# STM32G081 register map
File version: 1.8
CPU: CM0 r0p1, little endian, MPU, no FPU, 2 interrupt priority bits
Registers are 32-bit, read-write, reset 0x0 unless marked. A register's access mark holds for its fields unless they carry their own. Offsets are from the block's base; [hi:lo] are bit positions; 'fields as' and 'values as' point back to an identical list.

## UCPD1 — USB Power Delivery interface
Base 0x4000A000
Same registers: UCPD2 0x4000A400
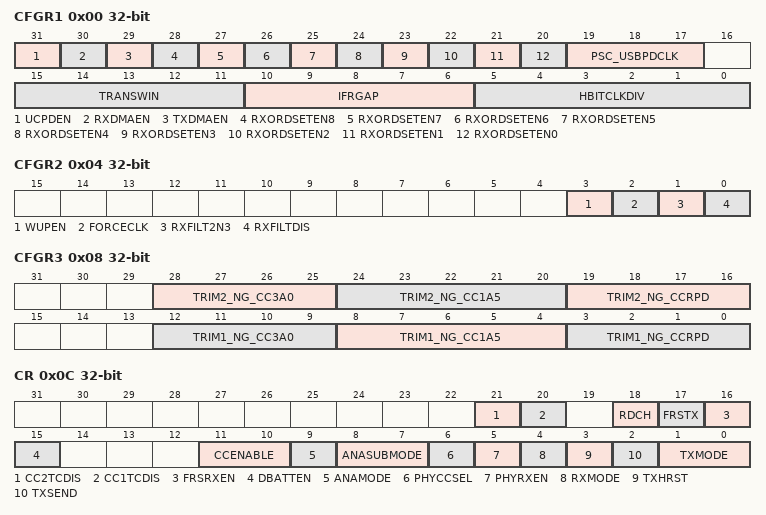
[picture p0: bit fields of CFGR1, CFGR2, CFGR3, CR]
0x00 CFGR1 — UCPD configuration register
  [31] UCPDEN
    0=Disabled (UCPD peripheral disabled); 1=Enabled (UCPD peripheral enabled)
  [30] RXDMAEN
    0=Disabled (DMA mode for reception disabled); 1=Enabled (DMA mode for reception enabled)
  [29] TXDMAEN
    0=Disabled (DMA mode for transmission disabled); 1=Enabled (DMA mode for transmission enabled)
  [28] RXORDSETEN8 — SOP extension #2
    0=Disabled (Flag disabled); 1=Enabled (Flag enabled)
  [27] RXORDSETEN7 — SOP extension #1
    0=Disabled (Flag disabled); 1=Enabled (Flag enabled)
  [26] RXORDSETEN6 — SOP'' Debug
    0=Disabled (Flag disabled); 1=Enabled (Flag enabled)
  [25] RXORDSETEN5 — SOP'_Debug
    0=Disabled (Flag disabled); 1=Enabled (Flag enabled)
  [24] RXORDSETEN4 — Cable Detect reset
    0=Disabled (Flag disabled); 1=Enabled (Flag enabled)
  [23] RXORDSETEN3 — Hard Reset detection
    0=Disabled (Flag disabled); 1=Enabled (Flag enabled)
  [22] RXORDSETEN2 — SOP'' detection
    0=Disabled (Flag disabled); 1=Enabled (Flag enabled)
  [21] RXORDSETEN1 — SOP' detection
    0=Disabled (Flag disabled); 1=Enabled (Flag enabled)
  [20] RXORDSETEN0 — SOP detection
    0=Disabled (Flag disabled); 1=Enabled (Flag enabled)
  [19:17] PSC_USBPDCLK
    0=Div1 (Divide by 1); 1=Div2 (Divide by 2); 2=Div4 (Divide by 4); 3=Div8 (Divide by 8); 4=Div16 (Divide by 16)
  [15:11] TRANSWIN range 1..31
  [10:6] IFRGAP range 1..31
  [5:0] HBITCLKDIV
0x04 CFGR2 — UCPD configuration register 2
  [3] WUPEN
    0=Disabled; 1=Enabled
  [2] FORCECLK
    0=NoForce (Do not force clock request); 1=Force clock request
  [1] RXFILT2N3
    0=Samp3 (3 samples); 1=Samp2 (2 samples)
  [0] RXFILTDIS
    0=Enabled (Rx pre-filter enabled); 1=Disabled (Rx pre-filter disabled)
0x08 CFGR3 — UCPD configuration register 3
  [28:25] TRIM2_NG_CC3A0, [24:20] TRIM2_NG_CC1A5 range 0..15, [19:16] TRIM2_NG_CCRPD, [12:9] TRIM1_NG_CC3A0, [8:4] TRIM1_NG_CC1A5 range 0..15, [3:0] TRIM1_NG_CCRPD
0x0C CR — UCPD control register
  [21] CC2TCDIS
    0=Enabled (Type-C detector on the CCx line enabled); 1=Disabled (Type-C detector on the CCx line disabled)
  [20] CC1TCDIS
    values as CC2TCDIS
  [18] RDCH
    0=NoEffect; 1=ConditionDrive (Rdch condition drive)
  [17] FRSTX
    0=NoEffect; 1=Enabled (FRS Tx signaling enabled)
  [16] FRSRXEN
    0=Disabled (FRS Rx event detection disabled); 1=Enabled (FRS Rx event detection enabled)
  [15] DBATTEN
    0=Disabled (Dead battery function disabled); 1=Enabled (Dead battery function enabled)
  [11:10] CCENABLE
    0=Disabled (Both PHYs disabled); 1=CC1Enabled (CC1 PHY enabled); 2=CC2Enabled (CC2 PHY enabled); 3=BothEnabled (CC1 and CC2 PHYs enabled)
  [9] ANAMODE
    0=Source; 1=Sink
  [8:7] ANASUBMODE
    0=Disabled; 1=Rp_DefaultUSB (Default USB Rp); 2=Rp_1_5A (1.5A Rp); 3=Rp_3A (3A Rp)
  [6] PHYCCSEL
    0=CC1 (Use CC1 IO for Power Delivery communication); 1=CC2 (Use CC2 IO for Power Delivery communication)
  [5] PHYRXEN
    0=Disabled (USB Power Delivery receiver disabled); 1=Enabled (USB Power Delivery receiver enabled)
  [4] RXMODE
    0=Normal receive mode; 1=BIST (BIST receive mode (BIST test data mode))
  [3] TXHRST
    0=NoEffect; 1=Start Tx Hard Reset message
  [2] TXSEND
    0=NoEffect; 1=Start Tx packet transmission
  [1:0] TXMODE
    0=RegisterSet (Transmission of Tx packet previously defined in other registers); 1=Cable Reset sequence; 2=BIST test sequence (BIST Carrier Mode 2)
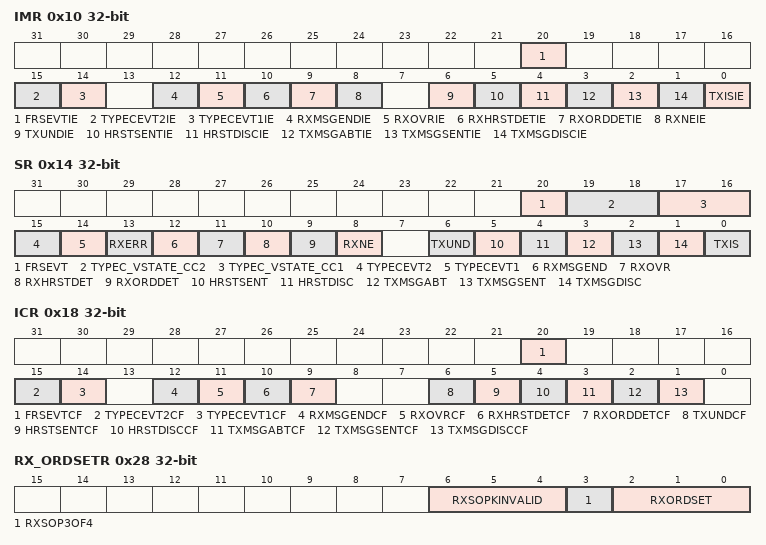
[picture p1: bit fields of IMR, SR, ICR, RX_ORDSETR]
0x10 IMR — UCPD Interrupt Mask Register
  [all] fields
    0=Disabled (Interrupt disabled); 1=Enabled (Interrupt enabled)
  [20] FRSEVTIE
  [15] TYPECEVT2IE
  [14] TYPECEVT1IE
  [12] RXMSGENDIE
  [11] RXOVRIE
  [10] RXHRSTDETIE
  [9] RXORDDETIE
  [8] RXNEIE
  [6] TXUNDIE
  [5] HRSTSENTIE
  [4] HRSTDISCIE
  [3] TXMSGABTIE
  [2] TXMSGSENTIE
  [1] TXMSGDISCIE
  [0] TXISIE
0x14 SR ro — UCPD Status Register
  [20] FRSEVT
    0=NoNewEvent; 1=NewEvent (New FRS receive event occurred)
  [19:18] TYPEC_VSTATE_CC2
    0=Lowest; 1=Low; 2=High; 3=Highest
  [17:16] TYPEC_VSTATE_CC1
    0=Lowest; 1=Low; 2=High; 3=Highest
  [15] TYPECEVT2
    0=NoNewEvent; 1=NewEvent (A new Type-C event occurred)
  [14] TYPECEVT1
    0=NoNewEvent; 1=NewEvent (A new Type-C event occurred)
  [13] RXERR
    0=No error detected; 1=Error(s) detected
  [12] RXMSGEND
    0=NoNewMessage (No new Rx message received); 1=NewMessage (A new Rx message received)
  [11] RXOVR
    0=NoOverflow; 1=Overflow
  [10] RXHRSTDET
    0=NoHardReset (Hard Reset not received); 1=Hard Reset received
  [9] RXORDDET
    0=No ordered set detected; 1=Ordered set detected
  [8] RXNE
    0=Empty (Rx data register empty); 1=NotEmpty (Rx data register not empty)
  [6] TXUND
    0=NoUnderrun (No Tx data underrun detected); 1=Underrun (Tx data underrun detected)
  [5] HRSTSENT
    0=NotSent (No Hard Reset message sent); 1=Sent (Hard Reset message sent)
  [4] HRSTDISC
    0=NotDiscarded (No Hard Reset discarded); 1=Discarded (Hard Reset discarded)
  [3] TXMSGABT
    0=NoAbort (No transmit message abort); 1=Abort (Transmit message abort)
  [2] TXMSGSENT
    0=NotCompleted (No Tx message completed); 1=Completed (Tx message completed)
  [1] TXMSGDISC
    0=NotDiscarded (No Tx message discarded); 1=Discarded (Tx message discarded)
  [0] TXIS
    0=NotRequired (New Tx data write not required); 1=Required (New Tx data write required)
0x18 ICR — UCPD Interrupt Clear Register
  [all] fields
    on write: 1=Clear flag in UCPD_SR
  [20] FRSEVTCF
  [15] TYPECEVT2CF
  [14] TYPECEVT1CF
  [12] RXMSGENDCF
  [11] RXOVRCF
  [10] RXHRSTDETCF
  [9] RXORDDETCF
  [6] TXUNDCF
  [5] HRSTSENTCF
  [4] HRSTDISCCF
  [3] TXMSGABTCF
  [2] TXMSGSENTCF
  [1] TXMSGDISCCF
0x1C TX_ORDSETR — UCPD Tx Ordered Set Type Register
  [19:0] TXORDSET
0x20 TX_PAYSZR — UCPD Tx Paysize Register
  [9:0] TXPAYSZ
0x24 TXDR — UCPD Tx Data Register
  [7:0] TXDATA
0x28 RX_ORDSETR ro — UCPD Rx Ordered Set Register
  [6:4] RXSOPKINVALID
    0=Valid (No K-code corrupted); 1=FirstCorrupted (First K-code corrupted); 2=SecondCorrupted (Second K-code corrupted); 3=ThirdCorrupted (Third K-code corrupted); 4=FourthCorrupted (Fourth K-code corrupted)
  [3] RXSOP3OF4
    0=AllCorrect (4 correct K-codes out of 4); 1=OneIncorrect (3 correct K-codes out of 4)
  [2:0] RXORDSET
    0=SOP (SOP code detected in receiver); 1=SOPPrime (SOP' code detected in receiver); 2=SOPDoublePrime (SOP'' code detected in receiver); 3=SOPPrimeDebug (SOP'_Debug detected in receiver); 4=SOPDoublePrimeDebug (SOP''_Debug detected in receiver); 5=Cable Reset detected in receiver; 6=SOP extension #1 detected in receiver; 7=SOP extension #2 detected in receiver
0x2C RX_PAYSZR — UCPD Rx Paysize Register
  [9:0] RXPAYSZ
0x30 RXDR ro — UCPD Receive Data Register
  [7:0] RXDATA
0x34 RX_ORDEXTR1 — UCPD Rx Ordered Set Extension Register
  [19:0] RXSOPX1
0x38 RX_ORDEXTR2 — UCPD Rx Ordered Set Extension Register
  [19:0] RXSOPX2
0x3F4 IPVER ro reset 0x10 — UCPD IP ID register
0x3F8 IPID ro reset 0x150021 — UCPD IP ID register
0x3FC MID ro reset 0xA3C5DD01 — UCPD IP ID register
  [31:0] IPID
